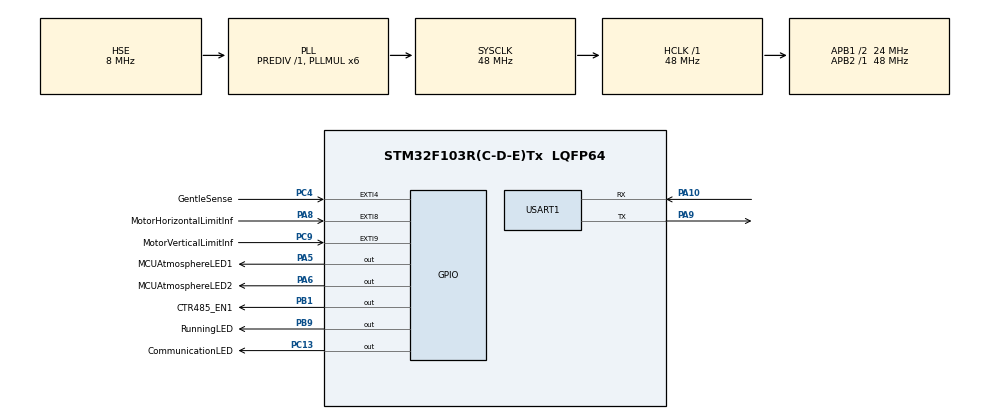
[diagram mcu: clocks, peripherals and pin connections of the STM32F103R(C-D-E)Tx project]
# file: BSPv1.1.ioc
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Mcu.Family=STM32F1
Mcu.Name=STM32F103R(C-D-E)Tx
Mcu.Package=LQFP64
NVIC.EXTI4_IRQn=true\:0\:0\:false\:true\:true\:2\:true
NVIC.EXTI9_5_IRQn=true\:0\:0\:false\:true\:true\:3\:true
NVIC.PriorityGroup=NVIC_PRIORITYGROUP_4
NVIC.TIM4_IRQn=true\:0\:0\:false\:true\:true\:4\:true
NVIC.TIM5_IRQn=true\:0\:0\:false\:true\:true\:5\:true
NVIC.USART1_IRQn=true\:0\:0\:false\:true\:true\:1\:true
PA10.Mode=Asynchronous
PA10.Signal=USART1_RX
PA13.Mode=Serial_Wire
PA13.Signal=SYS_JTMS-SWDIO
PA14.Mode=Serial_Wire
PA14.Signal=SYS_JTCK-SWCLK
PA5.GPIO_Label=MCUAtmosphereLED1
PA5.Signal=GPIO_Output
PA6.GPIO_Label=MCUAtmosphereLED2
PA6.Signal=GPIO_Output
PA8.GPIO_Label=MotorHorizontalLimitInf
PA8.Signal=GPXTI8
PA9.Mode=Asynchronous
PA9.Signal=USART1_TX
PB1.GPIO_Label=CTR485_EN1
PB1.Signal=GPIO_Output
PB9.GPIO_Label=RunningLED
PB9.Signal=GPIO_Output
PC13-TAMPER-RTC.GPIO_Label=CommunicationLED
PC13-TAMPER-RTC.Signal=GPIO_Output
PC4.GPIO_Label=GentleSense
PC4.Signal=GPXTI4
PC9.GPIO_Label=MotorVerticalLimitInf
PC9.Signal=GPXTI9
PD0-OSC_IN.Mode=HSE-External-Oscillator
PD0-OSC_IN.Signal=RCC_OSC_IN
PD1-OSC_OUT.Mode=HSE-External-Oscillator
PD1-OSC_OUT.Signal=RCC_OSC_OUT
ProjectManager.HeapSize=0x200
ProjectManager.StackSize=0x400
ProjectManager.TargetToolchain=MDK-ARM V5
RCC.AHBFreq_Value=48000000
RCC.APB1CLKDivider=RCC_HCLK_DIV2
RCC.APB1Freq_Value=24000000
RCC.APB1TimFreq_Value=48000000
RCC.APB2Freq_Value=48000000
RCC.APB2TimFreq_Value=48000000
RCC.HCLKFreq_Value=48000000
RCC.PLLMUL=RCC_PLL_MUL6
RCC.PLLSourceVirtual=RCC_PLLSOURCE_HSE
RCC.SYSCLKFreq_VALUE=48000000
RCC.SYSCLKSource=RCC_SYSCLKSOURCE_PLLCLK
RCC.USBFreq_Value=48000000
TIM4.Period=1000-1
TIM4.Prescaler=48-1
TIM5.Period=1000-1
TIM5.Prescaler=48-1
USART1.VirtualMode=VM_ASYNC
VP_TIM4_VS_ClockSourceINT.Mode=Internal
VP_TIM5_VS_ClockSourceINT.Mode=Internal
board=BSPv1.1

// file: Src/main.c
/**
  ******************************************************************************
  * File Name          : main.c
  * Description        : Main program body
  ******************************************************************************
  ** This notice applies to any and all portions of this file
  * that are not between comment pairs USER CODE BEGIN and
  * USER CODE END. Other portions of this file, whether
  * inserted by the user or by software development tools
  * are owned by their respective copyright owners.
  *
  * COPYRIGHT(c) 2017 STMicroelectronics
  *
  * Redistribution and use in source and binary forms, with or without modification,
  * are permitted provided that the following conditions are met:
  *   1. Redistributions of source code must retain the above copyright notice,
  *      this list of conditions and the following disclaimer.
  *   2. Redistributions in binary form must reproduce the above copyright notice,
  *      this list of conditions and the following disclaimer in the documentation
  *      and/or other materials provided with the distribution.
  *   3. Neither the name of STMicroelectronics nor the names of its contributors
  *      may be used to endorse or promote products derived from this software
  *      without specific prior written permission.
  *
  * THIS SOFTWARE IS PROVIDED BY THE COPYRIGHT HOLDERS AND CONTRIBUTORS "AS IS"
  * AND ANY EXPRESS OR IMPLIED WARRANTIES, INCLUDING, BUT NOT LIMITED TO, THE
  * IMPLIED WARRANTIES OF MERCHANTABILITY AND FITNESS FOR A PARTICULAR PURPOSE ARE
  * DISCLAIMED. IN NO EVENT SHALL THE COPYRIGHT HOLDER OR CONTRIBUTORS BE LIABLE
  * FOR ANY DIRECT, INDIRECT, INCIDENTAL, SPECIAL, EXEMPLARY, OR CONSEQUENTIAL
  * DAMAGES (INCLUDING, BUT NOT LIMITED TO, PROCUREMENT OF SUBSTITUTE GOODS OR
  * SERVICES; LOSS OF USE, DATA, OR PROFITS; OR BUSINESS INTERRUPTION) HOWEVER
  * CAUSED AND ON ANY THEORY OF LIABILITY, WHETHER IN CONTRACT, STRICT LIABILITY,
  * OR TORT (INCLUDING NEGLIGENCE OR OTHERWISE) ARISING IN ANY WAY OUT OF THE USE
  * OF THIS SOFTWARE, EVEN IF ADVISED OF THE POSSIBILITY OF SUCH DAMAGE.
  *
  ******************************************************************************
  */
#include "main.h"
#include "stm32f1xx_hal.h"
#include "tim.h"
#include "usart.h"
#include "gpio.h"

/* USER CODE BEGIN PV */
/* Private variables ---------------------------------------------------------*/
uint16_t gTIM4Cnt = 0;
uint8_t testCharBuf[10] = {0xAA, 0xBB, 0xAB, 0xCC, 0xDD, 0xEE, 0xFF, 0xCD, 0xEF, 0xBF};
/* USER CODE END PV */

void SystemClock_Config(void);
static void MX_NVIC_Init(void);

/* USER CODE BEGIN PFP */
/* Private function prototypes -----------------------------------------------*/

/* USER CODE END PFP */

int main(void)
{

  /* MCU Configuration----------------------------------------------------------*/

  /* Reset of all peripherals, Initializes the Flash interface and the Systick. */
  HAL_Init();

  /* Configure the system clock */
  SystemClock_Config();

  /* Initialize all configured peripherals */
  MX_GPIO_Init();
  MX_USART1_UART_Init();
  MX_TIM4_Init();
  MX_TIM5_Init();

  /* Initialize interrupts */
  MX_NVIC_Init();

  /* USER CODE BEGIN 2 */
	HAL_TIM_Base_Start_IT(&htim4);

  /* USER CODE END 2 */

  /* Infinite loop */
  while (1)
  {

  /* USER CODE BEGIN 3 */
		BSP_SendDate2DriverBoard(testCharBuf,10,0xFFFF);
		HAL_Delay(100);
  }
  /* USER CODE END 3 */

}

/** System Clock Configuration
*/
void SystemClock_Config(void)
{

  RCC_OscInitTypeDef RCC_OscInitStruct;
  RCC_ClkInitTypeDef RCC_ClkInitStruct;

    /**Initializes the CPU, AHB and APB busses clocks
    */
  RCC_OscInitStruct.OscillatorType = RCC_OSCILLATORTYPE_HSE;
  RCC_OscInitStruct.HSEState = RCC_HSE_ON;
  RCC_OscInitStruct.HSEPredivValue = RCC_HSE_PREDIV_DIV1;
  RCC_OscInitStruct.HSIState = RCC_HSI_ON;
  RCC_OscInitStruct.PLL.PLLState = RCC_PLL_ON;
  RCC_OscInitStruct.PLL.PLLSource = RCC_PLLSOURCE_HSE;
  RCC_OscInitStruct.PLL.PLLMUL = RCC_PLL_MUL6;
  if (HAL_RCC_OscConfig(&RCC_OscInitStruct) != HAL_OK)
  {
    _Error_Handler(__FILE__, __LINE__);
  }

    /**Initializes the CPU, AHB and APB busses clocks
    */
  RCC_ClkInitStruct.ClockType = RCC_CLOCKTYPE_HCLK|RCC_CLOCKTYPE_SYSCLK
                              |RCC_CLOCKTYPE_PCLK1|RCC_CLOCKTYPE_PCLK2;
  RCC_ClkInitStruct.SYSCLKSource = RCC_SYSCLKSOURCE_PLLCLK;
  RCC_ClkInitStruct.AHBCLKDivider = RCC_SYSCLK_DIV1;
  RCC_ClkInitStruct.APB1CLKDivider = RCC_HCLK_DIV2;
  RCC_ClkInitStruct.APB2CLKDivider = RCC_HCLK_DIV1;

  if (HAL_RCC_ClockConfig(&RCC_ClkInitStruct, FLASH_LATENCY_1) != HAL_OK)
  {
    _Error_Handler(__FILE__, __LINE__);
  }

    /**Configure the Systick interrupt time
    */
  HAL_SYSTICK_Config(HAL_RCC_GetHCLKFreq()/1000);

    /**Configure the Systick
    */
  HAL_SYSTICK_CLKSourceConfig(SYSTICK_CLKSOURCE_HCLK);

  /* SysTick_IRQn interrupt configuration */
  HAL_NVIC_SetPriority(SysTick_IRQn, 0, 0);
}

/** NVIC Configuration
*/
static void MX_NVIC_Init(void)
{
  /* USART1_IRQn interrupt configuration */
  HAL_NVIC_SetPriority(USART1_IRQn, 0, 0);
  HAL_NVIC_EnableIRQ(USART1_IRQn);
  /* EXTI4_IRQn interrupt configuration */
  HAL_NVIC_SetPriority(EXTI4_IRQn, 0, 0);
  HAL_NVIC_EnableIRQ(EXTI4_IRQn);
  /* EXTI9_5_IRQn interrupt configuration */
  HAL_NVIC_SetPriority(EXTI9_5_IRQn, 0, 0);
  HAL_NVIC_EnableIRQ(EXTI9_5_IRQn);
  /* TIM4_IRQn interrupt configuration */
  HAL_NVIC_SetPriority(TIM4_IRQn, 0, 0);
  HAL_NVIC_EnableIRQ(TIM4_IRQn);
  /* TIM5_IRQn interrupt configuration */
  HAL_NVIC_SetPriority(TIM5_IRQn, 0, 0);
  HAL_NVIC_EnableIRQ(TIM5_IRQn);
}

/* USER CODE BEGIN 4 */
void HAL_TIM_PeriodElapsedCallback(TIM_HandleTypeDef *htim)
{
	if(htim->Instance == htim4.Instance)
	{
		gTIM4Cnt++;
			if(gTIM4Cnt > 100)
			{
				BSP_COMMUNICATIONLED_TORGGLE();
				BSP_RUNNINGLED_TORGGLE();
				gTIM4Cnt = 0;
			}

	}

	if(htim->Instance == htim5.Instance)
	{

	}
}

/* USER CODE END 4 */

void _Error_Handler(char * file, int line)
{
  while(1)
  {
  }
}

/************************ (C) COPYRIGHT STMicroelectronics *****END OF FILE****/
